# R7FA8M1AH register map
Vendor: Renesas; Series: RA8; File version: 1.2
CPU: CM85 r0p0, little endian, MPU, FPU, VTOR, 4 interrupt priority bits
Registers are 32-bit, read-write, reset 0x0 unless marked. A register's access mark holds for its fields unless they carry their own. Offsets are from the block's base; [hi:lo] are bit positions; 'fields as' and 'values as' point back to an identical list.

## TSD — Temperature Sensor Data
Base 0x4011B17C
Same registers: TSD_NS 0x5011B17C
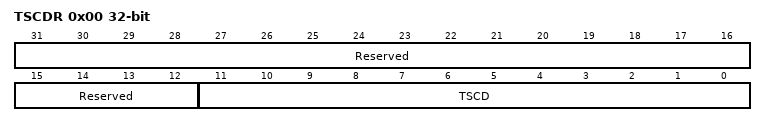
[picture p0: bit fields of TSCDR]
0x00 TSCDR ro (reset mask 0xFFFFF000) — Temperature Sensor Calibration Data Register
  [31:12] Reserved — These bits are read as 00000000000000000000.
  [11:0] TSCD — Temperature sensor calibration data is a digital value obtained using the 12-bit A/D converter unit 0 to convert the voltage output by the temperature sensor under the condition Ta = Tj = 127°C and AVCC0 = 3.3 V.

## FLAD — Data Flash
Base 0x4011C000
Same registers: FLAD_NS 0x5011C000
0x40 FCKMHZ 8-bit reset 0x3C (reset mask 0xC3) — Data Flash Reading Access Clock Frequency Register
  [7:0] FCKMHZ — Data Flash Reading Access Clock FrequencyNotifies operating frequency of clkf. Round up operating frequency in MHz unit, convert to binary, and write it to FCKMHZ bits.example) clkf = 35.9MHz (FCKMHZ = H'24)Round up 35.9Convert 36 to binary

## IWDT — Independent Watchdog Timer
Base 0x40202200
Same registers: IWDT_NS 0x50202200
0x00 IWDTRR 8-bit reset 0xFF — IWDT Refresh Register
  [7:0] IWDTRR — The down-counter is refreshed by writing 00h and then writing FFh to this register.
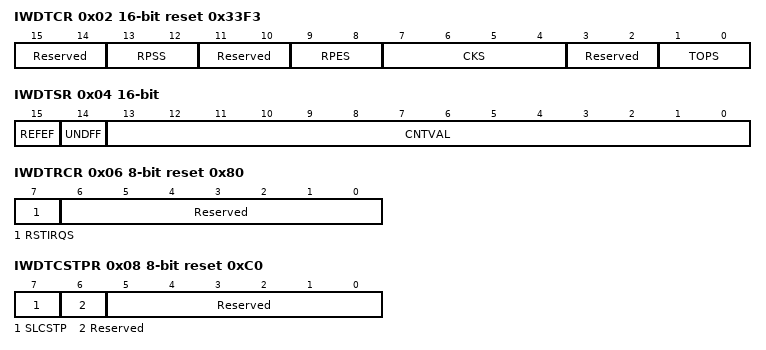
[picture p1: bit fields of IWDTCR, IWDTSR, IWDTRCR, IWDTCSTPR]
0x02 IWDTCR 16-bit reset 0x33F3 — IWDT Control Register
  [15:14] Reserved — These bits are read as 00. The write value should be 00.
  [13:12] RPSS — Window Start Position Select
    0=25%; 1=50%; 2=75%; 3=100% (do not specify window start position)
  [11:10] Reserved — These bits are read as 00. The write value should be 00.
  [9:8] RPES — Window End Position Select
    0=75%; 1=50%; 2=25%; 3=0% (do not specify window end position)
  [7:4] CKS — Clock Division Ratio Select
    0=OCOCLK; 2=OCOCLK/16; 3=OCOCLK/32; 4=OCOCLK/64; 7=OCOCLK/128; 5=OCOCLK/256
  [3:2] Reserved — These bits are read as 00. The write value should be 00.
  [1:0] TOPS — Timeout Period Select
    0=1024 cycles (03FFh); 1=4096 cycles (0FFFh); 2=8192 cycles (1FFFh); 3=16384 cycles (3FFFh); 0=128 cycles (007Fh); 1=512 cycles (01FFh); 2=1024 cycles (03FFh); 3=2048 cycles (07FFh)
0x04 IWDTSR 16-bit — IWDT Status Register
  [15] REFEF — Refresh Error Flag
    0=No refresh error occurred; 1=Refresh error occurred
  [14] UNDFF — Underflow Flag
    0=No underflow occurred; 1=Underflow occurred
  [13:0] CNTVAL ro — Down-Counter Value
0x06 IWDTRCR 8-bit reset 0x80 — IWDT Reset Control Register
  [7] RSTIRQS — Reset Interrupt Request Select
    0=Non-maskable interrupt request or interrupt request output; 1=Reset output is enabled
  [6:0] Reserved — These bits are read as 0000000. The write value should be 0000000.
0x08 IWDTCSTPR 8-bit reset 0xC0 — IWDT Count Stop Control Register
  [7] SLCSTP — Sleep-Mode Count Stop Control
    0=Count stop is disabled; 1=Count is stopped when transition to Sleep mode
  [6] Reserved — This bits is read as 1. The write value should be 1.
  [5:0] Reserved — These bits are read as 000000. The write value should be 000000.

## CAC — Clock Frequency Accuracy Measurement Circuit
Base 0x40202400
Same registers: CAC_NS 0x50202400
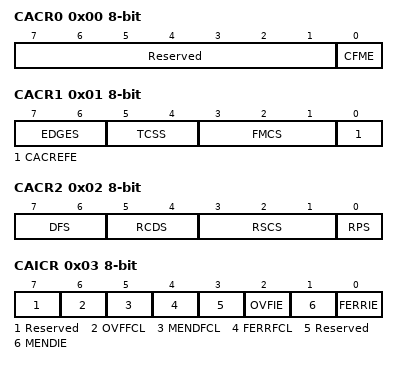
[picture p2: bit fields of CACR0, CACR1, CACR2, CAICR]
0x00 CACR0 8-bit — CAC Control Register 0
  [7:1] Reserved — These bits are read as 0000000. The write value should be 0000000.
  [0] CFME — Clock Frequency Measurement Enable.
    0=Disable; 1=Enable
0x01 CACR1 8-bit — CAC Control Register 1
  [7:6] EDGES — Valid Edge Select
    0=Rising edge; 1=Falling edge; 2=Both rising and falling edges; 3=Setting prohibited
  [5:4] TCSS — Measurement Target Clock Frequency Division Ratio Select
    0=No division; 1=x 1/4 clock; 2=x 1/8 clock; 3=x 1/32 clock
  [3:1] FMCS — Measurement Target Clock Select
    0=Main clock; 1=Sub-clock; 2=HOCO clock; 3=MOCO clock; 4=LOCO clock; 5=Peripheral module clock(PCLKB); 6=IWDTCLK clock; 7=Setting prohibited
  [0] CACREFE — CACREF Pin Input Enable
    0=Disable; 1=Enable
0x02 CACR2 8-bit — CAC Control Register 2
  [7:6] DFS — Digital Filter Selection
    0=Digital filtering is disabled; 1=The sampling clock for the digital filter is the frequency measuring clock; 2=The sampling clock for the digital filter is the frequency measuring clock divided by 4; 3=The sampling clock for the digital filter is the frequency measuring clock divided by 16
  [5:4] RCDS — Measurement Reference Clock Frequency Division Ratio Select
    0=1/32 clock; 1=1/128 clock; 2=1/1024 clock; 3=1/8192 clock
  [3:1] RSCS — Measurement Reference Clock Select
    values as CACR1.FMCS
  [0] RPS — Reference Signal Select
    0=CACREF pin input; 1=Internal clock (internally generated signal)
0x03 CAICR 8-bit — CAC Interrupt Control Register
  [7] Reserved — This bit is read as 0. The write value should be 0.
  [6] OVFFCL wo — OVFF Clear
    0=No effect on operations; 1=Clears the OVFF flag
  [5] MENDFCL wo — MENDF Clear
    0=No effect on operations; 1=Clears the MENDF flag
  [4] FERRFCL wo — FERRF Clear
    0=No effect on operations; 1=Clears the FERRF flag
  [3] Reserved — This bit is read as 0. The write value should be 0.
  [2] OVFIE — Overflow Interrupt Request Enable
    0=Disable; 1=Enable
  [1] MENDIE — Measurement End Interrupt Request Enable
    0=Disable; 1=Enable
  [0] FERRIE — Frequency Error Interrupt Request Enable
    0=Disable; 1=Enable
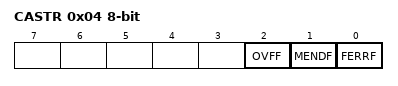
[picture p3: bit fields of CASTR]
0x04 CASTR 8-bit ro — CAC Status Register
  [2] OVFF — Counter Overflow Flag
    0=The counter has not overflowed; 1=The counter has overflowed
  [1] MENDF — Measurement End Flag
    0=Measurement is in progress; 1=Measurement has ended
  [0] FERRF — Frequency Error Flag
    0=The clock frequency is within the range corresponding to the settings; 1=The clock frequency has deviated beyond the range corresponding to the settings (frequency error)
0x06 CAULVR 16-bit — CAC Upper-Limit Value Setting Register
  [15:0] CAULVR — CAULVR is a 16-bit readable/writable register that stores the upper-limit value of the frequency.
0x08 CALLVR 16-bit — CAC Lower-Limit Value Setting Register
  [15:0] CALLVR — CALLVR is a 16-bit readable/writable register that stores the lower-limit value of the frequency.
0x0A CACNTBR 16-bit ro — CAC Counter Buffer Register
  [15:0] CACNTBR — CACNTBR is a 16-bit read-only register that retains the counter value at the time a valid reference signal edge is input
